# iospear320 register map
Registers are 32-bit, access not given, no defined reset value unless marked. A register's access mark holds for its fields unless they carry their own. Addresses are absolute; registers are grouped by the start of their names; [hi:lo] are bit positions; {n}, {i} and the like mark numbered series; 'fields as' and 'values as' point back to an identical list.

## SFR
0x40000060 timeout_reg
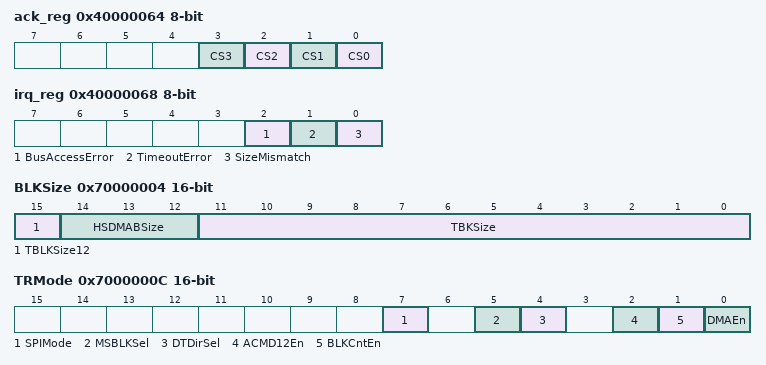
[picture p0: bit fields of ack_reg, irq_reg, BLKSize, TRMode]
0x40000064 ack_reg 8-bit
  [n] CS{n} (n=0..3)
0x40000068 irq_reg 8-bit
  [2] BusAccessError, [1] TimeoutError, [0] SizeMismatch
0x70000000 SDMASysAddr
0x70000004 BLKSize 16-bit
  [15] TBLKSize12, [14:12] HSDMABSize, [11:0] TBKSize
0x70000006 BLKCnt 16-bit
0x70000008 CMDARG
0x7000000C TRMode 16-bit
  [7] SPIMode, [5] MSBLKSel, [4] DTDirSel, [2] ACMD12En, [1] BLKCntEn, [0] DMAEn
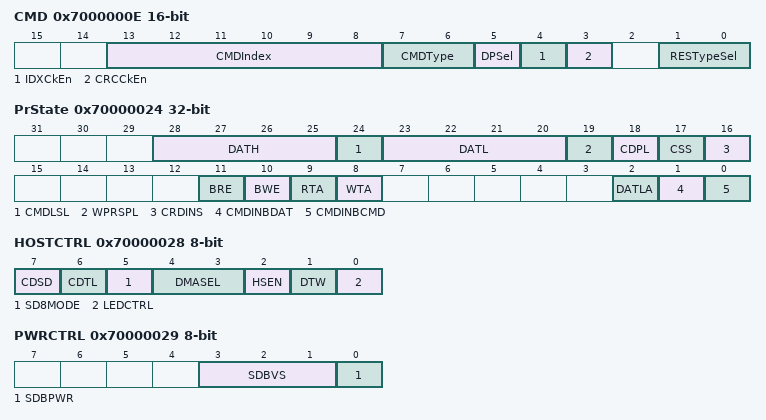
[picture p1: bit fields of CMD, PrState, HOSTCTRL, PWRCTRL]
0x7000000E CMD 16-bit
  [13:8] CMDIndex, [7:6] CMDType, [5] DPSel, [4] IDXCkEn, [3] CRCCkEn, [1:0] RESTypeSel
{0x70000010+4i} RESP{i} (i=0..3)
0x70000020 BufDataPort
0x70000024 PrState
  [28:25] DATH, [24] CMDLSL, [23:20] DATL, [19] WPRSPL, [18] CDPL, [17] CSS, [16] CRDINS, [11] BRE, [10] BWE, [9] RTA, [8] WTA, [2] DATLA, [1] CMDINBDAT, [0] CMDINBCMD
0x70000028 HOSTCTRL 8-bit
  [7] CDSD, [6] CDTL, [5] SD8MODE, [4:3] DMASEL, [2] HSEN, [1] DTW, [0] LEDCTRL
0x70000029 PWRCTRL 8-bit
  [3:1] SDBVS, [0] SDBPWR
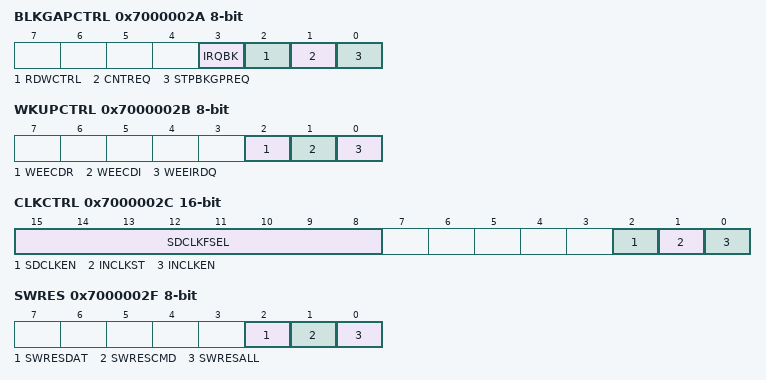
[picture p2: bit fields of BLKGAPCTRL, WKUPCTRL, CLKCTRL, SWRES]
0x7000002A BLKGAPCTRL 8-bit
  [3] IRQBK, [2] RDWCTRL, [1] CNTREQ, [0] STPBKGPREQ
0x7000002B WKUPCTRL 8-bit
  [2] WEECDR, [1] WEECDI, [0] WEEIRDQ
0x7000002C CLKCTRL 16-bit
  [15:8] SDCLKFSEL, [2] SDCLKEN, [1] INCLKST, [0] INCLKEN
0x7000002E TMOUTCTRL 8-bit
  [3:0] DATATMCNT
0x7000002F SWRES 8-bit
  [2] SWRESDAT, [1] SWRESCMD, [0] SWRESALL
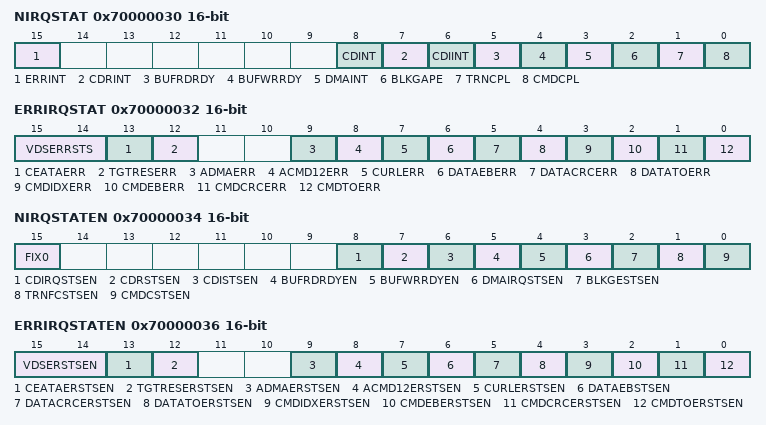
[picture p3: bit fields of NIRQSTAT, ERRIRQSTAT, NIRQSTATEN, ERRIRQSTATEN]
0x70000030 NIRQSTAT 16-bit
  [15] ERRINT, [8] CDINT, [7] CDRINT, [6] CDIINT, [5] BUFRDRDY, [4] BUFWRRDY, [3] DMAINT, [2] BLKGAPE, [1] TRNCPL, [0] CMDCPL
0x70000032 ERRIRQSTAT 16-bit
  [15:14] VDSERRSTS, [13] CEATAERR, [12] TGTRESERR, [9] ADMAERR, [8] ACMD12ERR, [7] CURLERR, [6] DATAEBERR, [5] DATACRCERR, [4] DATATOERR, [3] CMDIDXERR, [2] CMDEBERR, [1] CMDCRCERR, [0] CMDTOERR
0x70000034 NIRQSTATEN 16-bit
  [15] FIX0, [8] CDIRQSTSEN, [7] CDRSTSEN, [6] CDISTSEN, [5] BUFRDRDYEN, [4] BUFWRRDYEN, [3] DMAIRQSTSEN, [2] BLKGESTSEN, [1] TRNFCSTSEN, [0] CMDCSTSEN
0x70000036 ERRIRQSTATEN 16-bit
  [15:14] VDSERSTSEN, [13] CEATAERSTSEN, [12] TGTRESERSTSEN, [9] ADMAERSTSEN, [8] ACMD12ERSTSEN, [7] CURLERSTSEN, [6] DATAEBSTSEN, [5] DATACRCERSTSEN, [4] DATATOERSTSEN, [3] CMDIDXERSTSEN, [2] CMDEBERSTSEN, [1] CMDCRCERSTSEN, [0] CMDTOERSTSEN
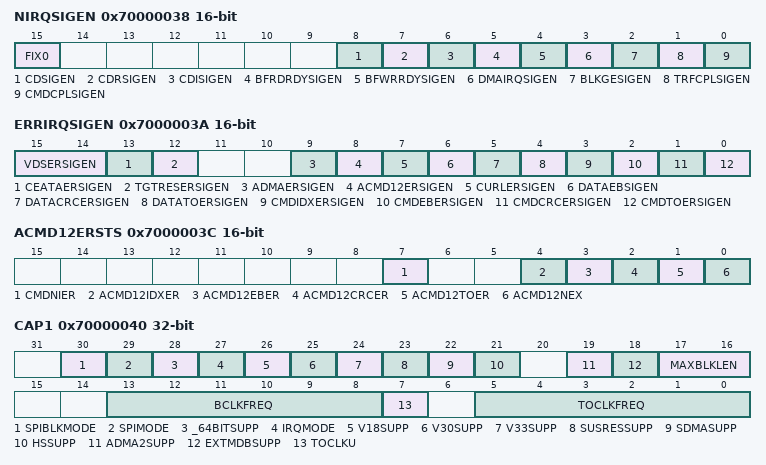
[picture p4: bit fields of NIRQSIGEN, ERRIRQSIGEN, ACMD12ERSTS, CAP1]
0x70000038 NIRQSIGEN 16-bit
  [15] FIX0, [8] CDSIGEN, [7] CDRSIGEN, [6] CDISIGEN, [5] BFRDRDYSIGEN, [4] BFWRRDYSIGEN, [3] DMAIRQSIGEN, [2] BLKGESIGEN, [1] TRFCPLSIGEN, [0] CMDCPLSIGEN
0x7000003A ERRIRQSIGEN 16-bit
  [15:14] VDSERSIGEN, [13] CEATAERSIGEN, [12] TGTRESERSIGEN, [9] ADMAERSIGEN, [8] ACMD12ERSIGEN, [7] CURLERSIGEN, [6] DATAEBSIGEN, [5] DATACRCERSIGEN, [4] DATATOERSIGEN, [3] CMDIDXERSIGEN, [2] CMDEBERSIGEN, [1] CMDCRCERSIGEN, [0] CMDTOERSIGEN
0x7000003C ACMD12ERSTS 16-bit
  [7] CMDNIER, [4] ACMD12IDXER, [3] ACMD12EBER, [2] ACMD12CRCER, [1] ACMD12TOER, [0] ACMD12NEX
0x70000040 CAP1
  [30] SPIBLKMODE, [29] SPIMODE, [28] _64BITSUPP, [27] IRQMODE, [26] V18SUPP, [25] V30SUPP, [24] V33SUPP, [23] SUSRESSUPP, [22] SDMASUPP, [21] HSSUPP, [19] ADMA2SUPP, [18] EXTMDBSUPP, [17:16] MAXBLKLEN, [13:8] BCLKFREQ, [7] TOCLKU, [5:0] TOCLKFREQ
0x70000044 CAP2
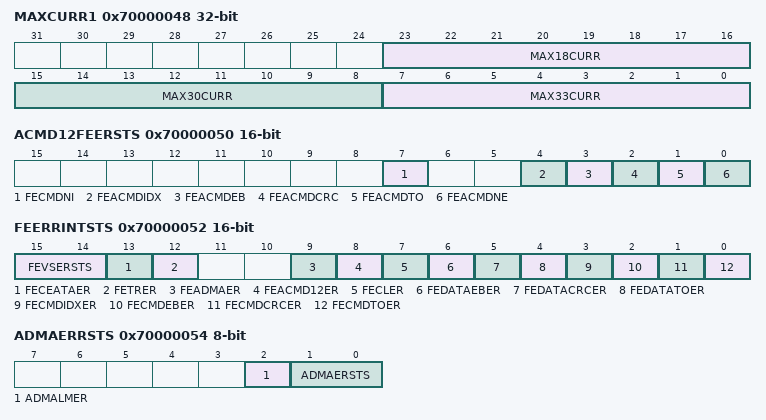
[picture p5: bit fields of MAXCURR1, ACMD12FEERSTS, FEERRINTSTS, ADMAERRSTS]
0x70000048 MAXCURR1
  [23:16] MAX18CURR, [15:8] MAX30CURR, [7:0] MAX33CURR
0x7000004C MAXCURR2
0x70000050 ACMD12FEERSTS 16-bit
  [7] FECMDNI, [4] FEACMDIDX, [3] FEACMDEB, [2] FEACMDCRC, [1] FEACMDTO, [0] FEACMDNE
0x70000052 FEERRINTSTS 16-bit
  [15:14] FEVSERSTS, [13] FECEATAER, [12] FETRER, [9] FEADMAER, [8] FEACMD12ER, [7] FECLER, [6] FEDATAEBER, [5] FEDATACRCER, [4] FEDATATOER, [3] FECMDIDXER, [2] FECMDEBER, [1] FECMDCRCER, [0] FECMDTOER
0x70000054 ADMAERRSTS 8-bit
  [2] ADMALMER, [1:0] ADMAERSTS
0x70000058 ADMAAddr1
0x7000005C ADMAAddr2
0x700000F0 SPIIRQSUPP 8-bit
0x700000FC SLTIRQSTS 8-bit
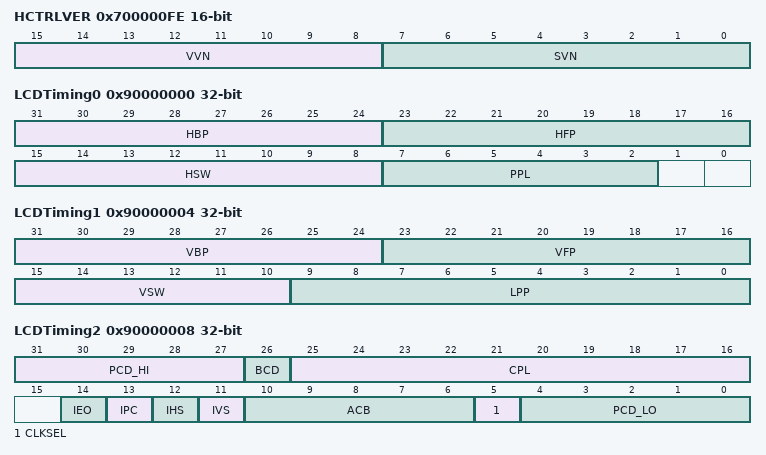
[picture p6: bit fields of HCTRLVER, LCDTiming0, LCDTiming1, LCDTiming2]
0x700000FE HCTRLVER 16-bit
  [15:8] VVN, [7:0] SVN
0x90000000 LCDTiming0
  [31:24] HBP, [23:16] HFP, [15:8] HSW, [7:2] PPL
0x90000004 LCDTiming1
  [31:24] VBP, [23:16] VFP, [15:10] VSW, [9:0] LPP
0x90000008 LCDTiming2
  [31:27] PCD_HI, [26] BCD, [25:16] CPL, [14] IEO, [13] IPC, [12] IHS, [11] IVS, [10:6] ACB, [5] CLKSEL, [4:0] PCD_LO
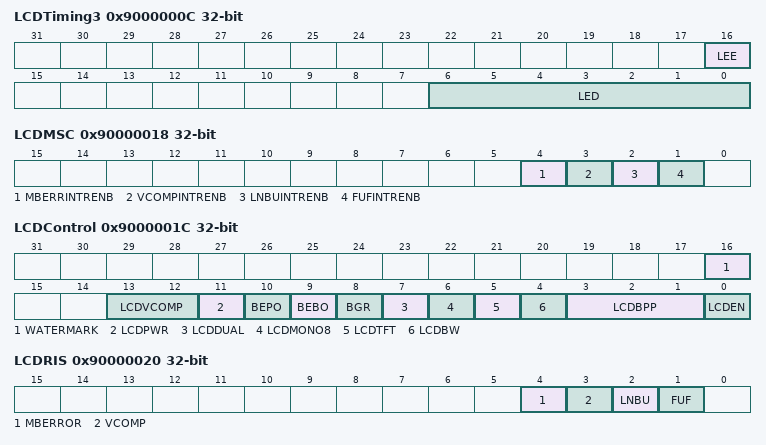
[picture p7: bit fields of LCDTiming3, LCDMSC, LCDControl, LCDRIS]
0x9000000C LCDTiming3
  [16] LEE, [6:0] LED
0x90000010 LCDUPBase
0x90000014 LCDLPBase
0x90000018 LCDMSC
  [4] MBERRINTRENB, [3] VCOMPINTRENB, [2] LNBUINTRENB, [1] FUFINTRENB
0x9000001C LCDControl
  [16] WATERMARK, [13:12] LCDVCOMP, [11] LCDPWR, [10] BEPO, [9] BEBO, [8] BGR, [7] LCDDUAL, [6] LCDMONO8, [5] LCDTFT, [4] LCDBW, [3:1] LCDBPP, [0] LCDEN
0x90000020 LCDRIS
  [4] MBERROR, [3] VCOMP, [2] LNBU, [1] FUF
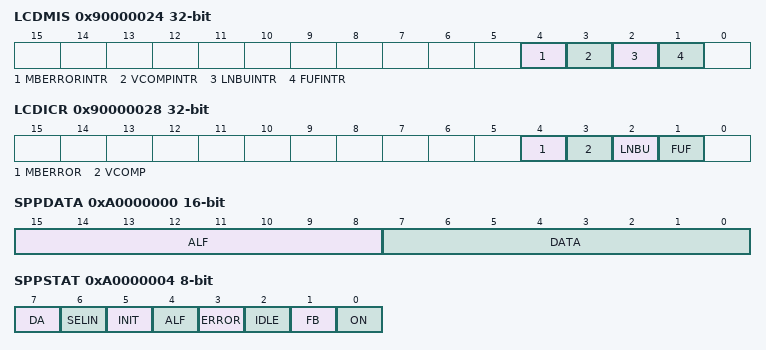
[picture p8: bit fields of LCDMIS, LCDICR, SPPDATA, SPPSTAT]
0x90000024 LCDMIS
  [4] MBERRORINTR, [3] VCOMPINTR, [2] LNBUINTR, [1] FUFINTR
0x90000028 LCDICR
  [4] MBERROR, [3] VCOMP, [2] LNBU, [1] FUF
0x9000002C LCDUPCUR
0x90000030 LCDLPCUR
0x90000200 LCDPaletteBase
{0x90000FE0+4i} LCDLPHERIPHID{i} (i=0..3)
{0x90000FF0+4i} LCDLPCELLIDID{i} (i=0..3)
0xA0000000 SPPDATA 16-bit
  [15:8] ALF, [7:0] DATA
0xA0000004 SPPSTAT 8-bit
  [7] DA, [6] SELIN, [5] INIT, [4] ALF, [3] ERROR, [2] IDLE, [1] FB, [0] ON
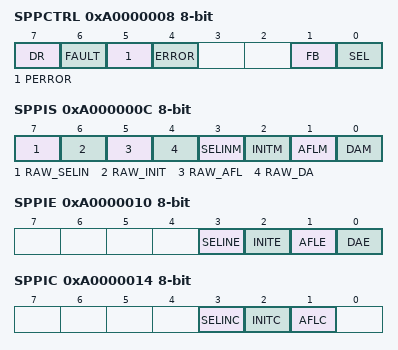
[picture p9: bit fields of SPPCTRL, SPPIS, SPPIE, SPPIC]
0xA0000008 SPPCTRL 8-bit
  [7] DR, [6] FAULT, [5] PERROR, [4] ERROR, [1] FB, [0] SEL
0xA000000C SPPIS 8-bit
  [7] RAW_SELIN, [6] RAW_INIT, [5] RAW_AFL, [4] RAW_DA, [3] SELINM, [2] INITM, [1] AFLM, [0] DAM
0xA0000010 SPPIE 8-bit
  [3] SELINE, [2] INITE, [1] AFLE, [0] DAE
0xA0000014 SPPIC 8-bit
  [3] SELINC, [2] INITC, [1] AFLC
0xA3000000 UART1DR 16-bit
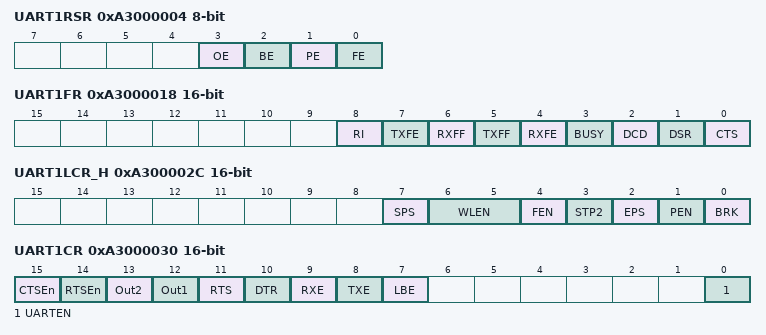
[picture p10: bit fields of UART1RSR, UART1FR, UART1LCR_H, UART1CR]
0xA3000004 UART1RSR 8-bit
  [3] OE, [2] BE, [1] PE, [0] FE
0xA3000004 UART1ECR 8-bit
0xA3000018 UART1FR 16-bit
  [8] RI, [7] TXFE, [6] RXFF, [5] TXFF, [4] RXFE, [3] BUSY, [2] DCD, [1] DSR, [0] CTS
0xA3000024 UART1IBRD 16-bit
0xA3000028 UART1FBRD 8-bit
  [5:0] DIVFRAC
0xA300002C UART1LCR_H 16-bit
  [7] SPS, [6:5] WLEN, [4] FEN, [3] STP2, [2] EPS, [1] PEN, [0] BRK
0xA3000030 UART1CR 16-bit
  [15] CTSEn, [14] RTSEn, [13] Out2, [12] Out1, [11] RTS, [10] DTR, [9] RXE, [8] TXE, [7] LBE, [0] UARTEN
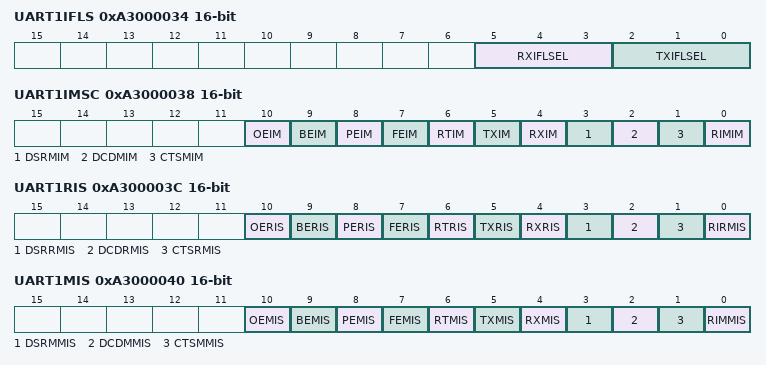
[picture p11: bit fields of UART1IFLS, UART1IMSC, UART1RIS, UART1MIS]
0xA3000034 UART1IFLS 16-bit
  [5:3] RXIFLSEL, [2:0] TXIFLSEL
0xA3000038 UART1IMSC 16-bit
  [10] OEIM, [9] BEIM, [8] PEIM, [7] FEIM, [6] RTIM, [5] TXIM, [4] RXIM, [3] DSRMIM, [2] DCDMIM, [1] CTSMIM, [0] RIMIM
0xA300003C UART1RIS 16-bit
  [10] OERIS, [9] BERIS, [8] PERIS, [7] FERIS, [6] RTRIS, [5] TXRIS, [4] RXRIS, [3] DSRRMIS, [2] DCDRMIS, [1] CTSRMIS, [0] RIRMIS
0xA3000040 UART1MIS 16-bit
  [10] OEMIS, [9] BEMIS, [8] PEMIS, [7] FEMIS, [6] RTMIS, [5] TXMIS, [4] RXMIS, [3] DSRMMIS, [2] DCDMMIS, [1] CTSMMIS, [0] RIMMIS
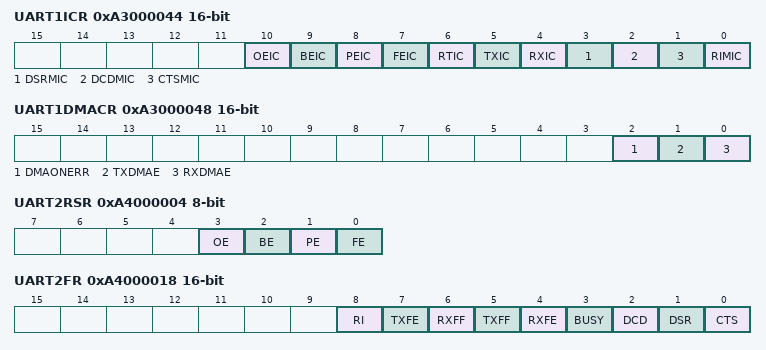
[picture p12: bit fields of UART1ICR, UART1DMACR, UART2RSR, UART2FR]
0xA3000044 UART1ICR 16-bit
  [10] OEIC, [9] BEIC, [8] PEIC, [7] FEIC, [6] RTIC, [5] TXIC, [4] RXIC, [3] DSRMIC, [2] DCDMIC, [1] CTSMIC, [0] RIMIC
0xA3000048 UART1DMACR 16-bit
  [2] DMAONERR, [1] TXDMAE, [0] RXDMAE
{0xA3000FE0+4i} UART1PeriphID{i} (i=0..3)
{0xA3000FF0+4i} UART1PCellID{i} (i=0..3)
0xA4000000 UART2DR 16-bit
0xA4000004 UART2RSR 8-bit
  [3] OE, [2] BE, [1] PE, [0] FE
0xA4000004 UART2ECR 8-bit
0xA4000018 UART2FR 16-bit
  fields as UART1FR
0xA4000024 UART2IBRD 16-bit
0xA4000028 UART2FBRD 8-bit
  [5:0] DIVFRAC
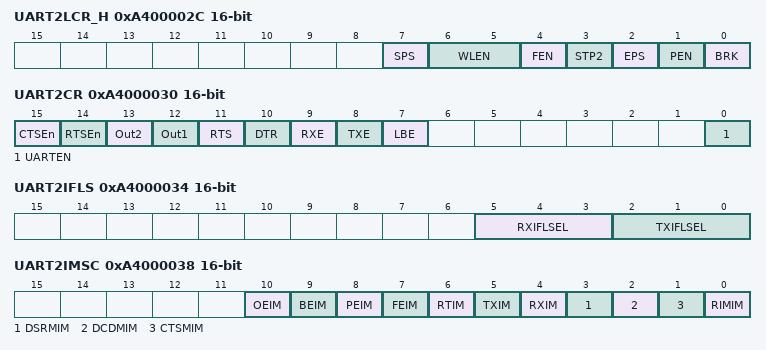
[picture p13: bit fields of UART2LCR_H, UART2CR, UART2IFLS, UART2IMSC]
0xA400002C UART2LCR_H 16-bit
  [7] SPS, [6:5] WLEN, [4] FEN, [3] STP2, [2] EPS, [1] PEN, [0] BRK
0xA4000030 UART2CR 16-bit
  fields as UART1CR
0xA4000034 UART2IFLS 16-bit
  [5:3] RXIFLSEL, [2:0] TXIFLSEL
0xA4000038 UART2IMSC 16-bit
  fields as UART1IMSC
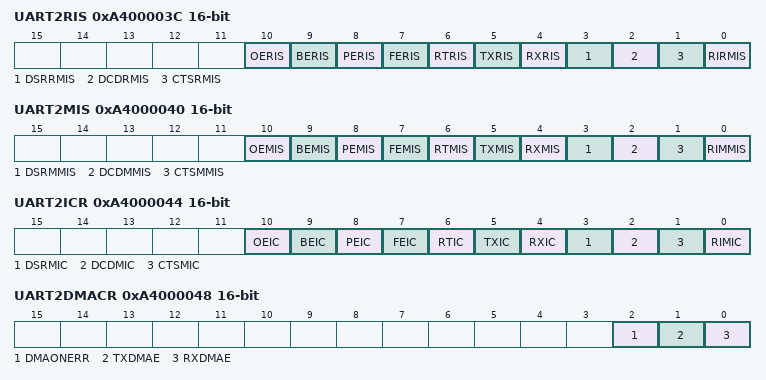
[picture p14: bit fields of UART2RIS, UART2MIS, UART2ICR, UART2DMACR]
0xA400003C UART2RIS 16-bit
  fields as UART1RIS
0xA4000040 UART2MIS 16-bit
  fields as UART1MIS
0xA4000044 UART2ICR 16-bit
  fields as UART1ICR
0xA4000048 UART2DMACR 16-bit
  [2] DMAONERR, [1] TXDMAE, [0] RXDMAE
{0xA4000FE0+4i} UART2PeriphID{i} (i=0..3)
{0xA4000FF0+4i} UART2PCellID{i} (i=0..3)
0xA5000000 SPI1CR0 16-bit
  [15:8] SCR, [7] SPH, [6] SPO, [5:4] FRF, [3:0] DSS
0xA5000004 SPI1CR1 16-bit
  [3] SOD, [2] MS, [1] SSE, [0] LBM
0xA5000008 SPI1DR 16-bit
0xA500000C SPI1SR 16-bit
  [4] BSY, [3] RFF, [2] RNE, [1] TNF, [0] TFE
0xA5000010 SPI1CPSR 16-bit
  [7:0] CPSDVSR
0xA5000014 SPI1IMSC 16-bit
  [3] TXIM, [2] RXIM, [1] RTIM, [0] RORIM
0xA5000018 SPI1RIS 16-bit
  [3] TXRIS, [2] RXRIS, [1] RTRIS, [0] RORRIS
0xA500001C SPI1MIS 16-bit
  [3] TXMIS, [2] RXMIS, [1] RTMIS, [0] RORMIS
0xA5000020 SPI1ICR 16-bit
  [1] RTIC, [0] RORIC
0xA5000024 SPI1DMACR 16-bit
  [1] TXDMAE, [0] RXDMAE
0xA5000FE0 SPI1PeriphID0 16-bit
  [7:0] PartNumber0
0xA5000FE4 SPI1PeriphID1 16-bit
  [7:4] Designer0, [3:0] PartNumber1
0xA5000FE8 SPI1PeriphID2 16-bit
  [7:4] Revision, [3:0] Designer1
0xA5000FEC SPI1PeriphID3 16-bit
  [7:0] Configuration
{0xA5000FF0+4i} SPI1CellID{i} 16-bit (i=0..3)
  [7:0] PCELLID{i}
0xA6000000 SPI2CR0 16-bit
  [15:8] SCR, [7] SPH, [6] SPO, [5:4] FRF, [3:0] DSS
0xA6000004 SPI2CR1 16-bit
  [3] SOD, [2] MS, [1] SSE, [0] LBM
0xA6000008 SPI2DR 16-bit
0xA600000C SPI2SR 16-bit
  [4] BSY, [3] RFF, [2] RNE, [1] TNF, [0] TFE
0xA6000010 SPI2CPSR 16-bit
  [7:0] CPSDVSR
0xA6000014 SPI2IMSC 16-bit
  [3] TXIM, [2] RXIM, [1] RTIM, [0] RORIM
0xA6000018 SPI2RIS 16-bit
  [3] TXRIS, [2] RXRIS, [1] RTRIS, [0] RORRIS
0xA600001C SPI2MIS 16-bit
  [3] TXMIS, [2] RXMIS, [1] RTMIS, [0] RORMIS
0xA6000020 SPI2ICR 16-bit
  [1] RTIC, [0] RORIC
0xA6000024 SPI2DMACR 16-bit
  [1] TXDMAE, [0] RXDMAE
0xA6000FE0 SPI2PeriphID0 16-bit
  [7:0] PartNumber0
0xA6000FE4 SPI2PeriphID1 16-bit
  [7:4] Designer0, [3:0] PartNumber1
0xA6000FE8 SPI2PeriphID2 16-bit
  [7:4] Revision, [3:0] Designer1
0xA6000FEC SPI2PeriphID3 16-bit
  [7:0] Configuration
{0xA6000FF0+4i} SPI2CellID{i} 16-bit (i=0..3)
  [7:0] PCELLID{i}
0xD0000000 UART0DR 16-bit
0xD0000004 UART0RSR 8-bit
  [3] OE, [2] BE, [1] PE, [0] FE
0xD0000004 UART0ECR 8-bit
0xD0000018 UART0FR 16-bit
  fields as UART1FR
0xD0000024 UART0IBRD 16-bit
0xD0000028 UART0FBRD 8-bit
  [5:0] DIVFRAC
0xD000002C UART0LCR_H 16-bit
  [7] SPS, [6:5] WLEN, [4] FEN, [3] STP2, [2] EPS, [1] PEN, [0] BRK
0xD0000030 UART0CR 16-bit
  fields as UART1CR
0xD0000034 UART0IFLS 16-bit
  [5:3] RXIFLSEL, [2:0] TXIFLSEL
0xD0000038 UART0IMSC 16-bit
  fields as UART1IMSC
0xD000003C UART0RIS 16-bit
  fields as UART1RIS
0xD0000040 UART0MIS 16-bit
  fields as UART1MIS
0xD0000044 UART0ICR 16-bit
  fields as UART1ICR
0xD0000048 UART0DMACR 16-bit
  [2] DMAONERR, [1] TXDMAE, [0] RXDMAE
{0xD0000FE0+4i} UART0PeriphID{i} (i=0..3)
{0xD0000FF0+4i} UART0PCellID{i} (i=0..3)
0xD0100000 SSPCR0 16-bit
  [15:8] SCR, [7] SPH, [6] SPO, [5:4] FRF, [3:0] DSS
0xD0100004 SSPCR1 16-bit
  [3] SOD, [2] MS, [1] SSE, [0] LBM
0xD0100008 SSPDR 16-bit
0xD010000C SSPSR 16-bit
  [4] BSY, [3] RFF, [2] RNE, [1] TNF, [0] TFE
0xD0100010 SSPCPSR 16-bit
  [7:0] CPSDVSR
0xD0100014 SSPIMSC 16-bit
  [3] TXIM, [2] RXIM, [1] RTIM, [0] RORIM
0xD0100018 SSPRIS 16-bit
  [3] TXRIS, [2] RXRIS, [1] RTRIS, [0] RORRIS
0xD010001C SSPMIS 16-bit
  [3] TXMIS, [2] RXMIS, [1] RTMIS, [0] RORMIS
0xD0100020 SSPICR 16-bit
  [1] RTIC, [0] RORIC
0xD0100024 SSPDMACR 16-bit
  [1] TXDMAE, [0] RXDMAE
0xD0100FE0 SSPPeriphID0 16-bit
  [7:0] PartNumber0
0xD0100FE4 SSPPeriphID1 16-bit
  [7:4] Designer0, [3:0] PartNumber1
0xD0100FE8 SSPPeriphID2 16-bit
  [7:4] Revision, [3:0] Designer1
0xD0100FEC SSPPeriphID3 16-bit
  [7:0] Configuration
{0xD0100FF0+4i} SSPCellID{i} 16-bit (i=0..3)
  [7:0] PCELLID{i}
0xD0800000 JPGCReg0
  [0] StartStop
0xD0800004 JPGCReg1
  [31:16] Ysiz, [8] Hdr, [7:6] Ns, [5:4] colspctype, [3] De, [2] Re, [1:0] Nf
0xD0800008 JPGCReg2
  [25:0] NMCU
0xD080000C JPGCReg3
  [31:16] Xsiz, [15:0] NRST
{0xD0800000+4i} JPGCReg{i} (i=4..7)
  [15:12] Vi, [11:8] Hi, [7:4] Nblocki, [3:2] QTi, [1] HAi, [0] HDi
0xD0800200 JPGCCS
  [31] EOC, [30] SCR, [17:3] LLI, [2:1] BNV, [0] INT
0xD0800204 JPGCBFIFO2C
0xD0800208 JPGCBC2FIFO
0xD080020C JPGCBCBI
  [31] EN, [30:0] BTF
0xD0800400 JPGCFifoIn
0xD0800600 JPGCFifoOut
0xD0800800 JPGCQMem
0xD0800C00 JPGCHuffMin
0xD0801000 JPGCHuffBase
0xD0801400 JPGCHuffSymb
0xD0801800 JPGCDHTMem
0xD0801C00 JPGCHuffEnc
0xE0800118 Txframecount_gb
0xE0800124 Tx64octects_gb
0xE0800128 Tx65to127octects_gb
0xE080012C Tx128to255octects_gb
0xE0800130 Tx256to511octects_gb
0xE0800134 Tx512to1023octects_gb
0xE0800138 Tx1024tomaxoctects_gb
0xE080013C Txunicastframes_gb
0xE0800148 Txunderflowerror
0xE080014C Txsinglecol_g
0xE0800150 Txmulticol_g
0xE0800154 Txdeferred
0xE0800158 Txlatecol
0xE080015C Txexesscol
0xE0800160 Txcarriererror
0xE0800168 Txexcessdef
0xE0800170 Txpauseframes
0xE0800174 Txvlanframes_g
0xE0800180 Rxframecount_gb
0xE080018C Rxbroadcastframes_g
0xE0800190 Rxmulticastframes_g
0xE0800194 Rxcrcerror
0xE0800198 Rxalignmenterror
0xE080019C Rxrunterror
0xE08001A0 Rxjabbererror
0xE08001A4 Rxundersize_g
0xE08001A8 Rxoversize_g
0xE08001AC Rx64octects_gb
0xE08001B0 Rx65to127octects_gb
0xE08001B4 Rx128to255octects_gb
0xE08001B8 Rx256to511octects_gb
0xE08001BC Rx512to1023octects_gb
0xE08001C0 Rx1023tomaxoctects_gb
0xE08001C4 Rxunicastframes_g
0xE08001C8 Rxlengtherror
0xE08001CC Rxoutofrangetype
0xE08001D0 Rxpauseframes
0xE08001D4 Rxfifooverflow
0xE08001D8 Rxvlanframes_gb
0xE08001DC Rxwatchdogerror
0xE1100000 UDEP0INCTRL
  [9] RRDY, [8] CNAK, [7] SNAK, [6] NAK, [5:4] ET, [3] P, [2] SN, [1] F, [0] S
0xE1100004 UDEP0INSTAT
  [23] ISOIN_DONE, [22:11] RX_PKT_SIZE, [10] TDC, [9] HE, [7] BNA, [6] IN, [5:4] OUT
0xE1100008 UDEP0INBS
  [17:16] ISO_PID, [15:0] BUFF_SIZE
0xE110000C UDEP0INMPS
  [31:16] BUFF_SIZE, [15:0] MAX_PKT_SIZE
0xE1100014 UDEP0INDDP
0xE1100018 UDEP0INWC
0xE1100020 UDEP1INCTRL
  fields as UDEP0INCTRL
0xE1100024 UDEP1INSTAT
  fields as UDEP0INSTAT
0xE1100028 UDEP1INBS
  [17:16] ISO_PID, [15:0] BUFF_SIZE
0xE110002C UDEP1INMPS
  [31:16] BUFF_SIZE, [15:0] MAX_PKT_SIZE
0xE1100034 UDEP1INDDP
0xE1100038 UDEP1INWC
0xE1100060 UDEP3INCTRL
  fields as UDEP0INCTRL
0xE1100064 UDEP3INSTAT
  fields as UDEP0INSTAT
0xE1100068 UDEP3INBS
  [17:16] ISO_PID, [15:0] BUFF_SIZE
0xE110006C UDEP3INMPS
  [31:16] BUFF_SIZE, [15:0] MAX_PKT_SIZE
0xE1100074 UDEP3INDDP
0xE1100078 UDEP3INWC
0xE11000A0 UDEP5INCTRL
  fields as UDEP0INCTRL
0xE11000A4 UDEP5INSTAT
  fields as UDEP0INSTAT
0xE11000A8 UDEP5INBS
  [17:16] ISO_PID, [15:0] BUFF_SIZE
0xE11000AC UDEP5INMPS
  [31:16] BUFF_SIZE, [15:0] MAX_PKT_SIZE
0xE11000B4 UDEP5INDDP
0xE11000B8 UDEP5INWC
0xE11000E0 UDEP7INCTRL
  fields as UDEP0INCTRL
0xE11000E4 UDEP7INSTAT
  fields as UDEP0INSTAT
0xE11000E8 UDEP7INBS
  [17:16] ISO_PID, [15:0] BUFF_SIZE
0xE11000EC UDEP7INMPS
  [31:16] BUFF_SIZE, [15:0] MAX_PKT_SIZE
0xE11000F4 UDEP7INDDP
0xE11000F8 UDEP7INWC
0xE1100120 UDEP9INCTRL
  fields as UDEP0INCTRL
0xE1100124 UDEP9INSTAT
  fields as UDEP0INSTAT
0xE1100128 UDEP9INBS
  [17:16] ISO_PID, [15:0] BUFF_SIZE
0xE110012C UDEP9INMPS
  [31:16] BUFF_SIZE, [15:0] MAX_PKT_SIZE
0xE1100134 UDEP9INDDP
0xE1100138 UDEP9INWC
0xE1100160 UDEP11INCTRL
  fields as UDEP0INCTRL
0xE1100164 UDEP11INSTAT
  fields as UDEP0INSTAT
0xE1100168 UDEP11INBS
  [17:16] ISO_PID, [15:0] BUFF_SIZE
0xE110016C UDEP11INMPS
  [31:16] BUFF_SIZE, [15:0] MAX_PKT_SIZE
0xE1100174 UDEP11INDDP
0xE1100178 UDEP11INWC
0xE11001A0 UDEP13INCTRL
  fields as UDEP0INCTRL
0xE11001A4 UDEP13INSTAT
  fields as UDEP0INSTAT
0xE11001A8 UDEP13INBS
  [17:16] ISO_PID, [15:0] BUFF_SIZE
0xE11001AC UDEP13INMPS
  [31:16] BUFF_SIZE, [15:0] MAX_PKT_SIZE
0xE11001B4 UDEP13INDDP
0xE11001B8 UDEP13INWC
0xE11001E0 UDEP15INCTRL
  fields as UDEP0INCTRL
0xE11001E4 UDEP15INSTAT
  fields as UDEP0INSTAT
0xE11001E8 UDEP15INBS
  [17:16] ISO_PID, [15:0] BUFF_SIZE
0xE11001EC UDEP15INMPS
  [31:16] BUFF_SIZE, [15:0] MAX_PKT_SIZE
0xE11001F4 UDEP15INDDP
0xE11001F8 UDEP15INWC
0xE1100200 UDEP0OUTCTRL
  fields as UDEP0INCTRL
0xE1100204 UDEP0OUTSTAT
  fields as UDEP0INSTAT
0xE1100208 UDEP0OUTPFN
  [17:16] ISO_PID, [15:0] BUFF_SIZE
0xE110020C UDEP0OUTBS
  [31:16] BUFF_SIZE, [15:0] MAX_PKT_SIZE
0xE1100210 UDEP0OUSBP
0xE1100214 UDEP0OUTDDP
0xE110021C UDEP0OUTRC
0xE1100240 UDEP2OUTCTRL
  fields as UDEP0INCTRL
0xE1100244 UDEP2OUTSTAT
  fields as UDEP0INSTAT
0xE1100248 UDEP2OUTPFN
  [17:16] ISO_PID, [15:0] BUFF_SIZE
0xE110024C UDEP2OUTBS
  [31:16] BUFF_SIZE, [15:0] MAX_PKT_SIZE
0xE1100250 UDEP2OUSBP
0xE1100254 UDEP2OUTDDP
0xE110025C UDEP2OUTRC
0xE1100280 UDEP4OUTCTRL
  fields as UDEP0INCTRL
0xE1100284 UDEP4OUTSTAT
  fields as UDEP0INSTAT
0xE1100288 UDEP4OUTPFN
  [17:16] ISO_PID, [15:0] BUFF_SIZE
0xE110028C UDEP4OUTBS
  [31:16] BUFF_SIZE, [15:0] MAX_PKT_SIZE
0xE1100290 UDEP4OUSBP
0xE1100294 UDEP4OUTDDP
0xE110029C UDEP4OUTRC
0xE11002C0 UDEP6OUTCTRL
  fields as UDEP0INCTRL
0xE11002C4 UDEP6OUTSTAT
  fields as UDEP0INSTAT
0xE11002C8 UDEP6OUTPFN
  [17:16] ISO_PID, [15:0] BUFF_SIZE
0xE11002CC UDEP6OUTBS
  [31:16] BUFF_SIZE, [15:0] MAX_PKT_SIZE
0xE11002D0 UDEP6OUSBP
0xE11002D4 UDEP6OUTDDP
0xE11002DC UDEP6OUTRC
0xE1100300 UDEP8OUTCTRL
  fields as UDEP0INCTRL
0xE1100304 UDEP8OUTSTAT
  fields as UDEP0INSTAT
0xE1100308 UDEP8OUTPFN
  [17:16] ISO_PID, [15:0] BUFF_SIZE
0xE110030C UDEP8OUTBS
  [31:16] BUFF_SIZE, [15:0] MAX_PKT_SIZE
0xE1100310 UDEP8OUSBP
0xE1100314 UDEP8OUTDDP
0xE110031C UDEP8OUTRC
0xE1100340 UDEP10OUTCTRL
  fields as UDEP0INCTRL
0xE1100344 UDEP10OUTSTAT
  fields as UDEP0INSTAT
0xE1100348 UDEP10OUTPFN
  [17:16] ISO_PID, [15:0] BUFF_SIZE
0xE110034C UDEP10OUTBS
  [31:16] BUFF_SIZE, [15:0] MAX_PKT_SIZE
0xE1100350 UDEP10OUSBP
0xE1100354 UDEP10OUTDDP
0xE110035C UDEP10OUTRC
0xE1100380 UDEP12OUTCTRL
  fields as UDEP0INCTRL
0xE1100384 UDEP12OUTSTAT
  fields as UDEP0INSTAT
0xE1100388 UDEP12OUTPFN
  [17:16] ISO_PID, [15:0] BUFF_SIZE
0xE110038C UDEP12OUTBS
  [31:16] BUFF_SIZE, [15:0] MAX_PKT_SIZE
0xE1100390 UDEP12OUSBP
0xE1100394 UDEP12OUTDDP
0xE110039C UDEP12OUTRC
0xE11003C0 UDEP14OUTCTRL
  fields as UDEP0INCTRL
0xE11003C4 UDEP14OUTSTAT
  fields as UDEP0INSTAT
0xE11003C8 UDEP14OUTPFN
  [17:16] ISO_PID, [15:0] BUFF_SIZE
0xE11003CC UDEP14OUTBS
  [31:16] BUFF_SIZE, [15:0] MAX_PKT_SIZE
0xE11003D0 UDEP14OUSBP
0xE11003D4 UDEP14OUTDDP
0xE11003DC UDEP14OUTRC
0xE1100400 UDDCFG
  [18] SET_DESC, [17] CSR_PRG, [16] HALT_STATUS, [15:13] HS_TIMEOUT_CALIB, [12:10] FS_TIMEOUT_CALIB, [9] PHY_ERROR_DETECT, [8] STATUS_1, [7] STATUS, [6] DIR, [5] PI, [4] SS, [3] SP, [2] RWKP, [1:0] SPD
0xE1100404 UDDCTRL
  [31:24] THLEN, [23:16] BRLEN, [13] CSR_DONE, [12] DEVNAK, [11] SCALE, [10] SD, [9] MODE, [8] BREN, [7] THE, [6] BF, [5] BE, [4] DU, [3] TDE, [2] RDE, [0] RES
0xE1100408 UDDSTAT
  [31:18] TS, [16] PHY_ERROR, [15] RXFIFO_EMPTY, [14:13] ENUM_SPD, [12] SUSP, [11:8] ALT, [7:4] INTF, [3:0] CFG
0xE110040C UDDINTR
  [6] ENUM, [5] SOF, [4] US, [3] UR, [2] ES, [1] SI, [0] SC
0xE1100410 UDDIM
  [6] ENUM, [5] SOF, [4] US, [3] UR, [2] ES, [1] SI, [0] SC
0xE1100414 UDEINTR
  [n+16] OUT_EP{n} (n=0..15), [n] IN_EP{n} (n=0..15)
0xE1100418 UDEIM
  [n+16] OUT_EP{n} (n=0..15), [n] IN_EP{n} (n=0..15)
{0xE1100504+4i} UDEP{i} (i=0..15)
  [29:19] MaxPackSize, [18:15] AltSetting, [14:11] InterfNumber, [10:7] ConfNumber, [6:5] EPType, [4] EPDir, [3:0] EPNumber
0xE1800000 HCCAPBASE
  [31:16] HCIVERSION, [7:0] CAPLENGTH
0xE1800004 HCSPARAMS
  [23:20] DPN, [16] P_INDICATOR, [15:12] N_CC, [11:8] N_PCC, [7] PRR, [4] PPC, [3:0] N_PORTS
0xE1800008 HCCPARAMS
  [15:8] EECP, [7:4] IST, [2] ASPC, [1] PFLF, [0] _64BAC
0xE1800010 HCUSBCMD
  [23:16] ITC, [11] ASPME, [9:8] ASPMC, [7] LHCR, [6] IAAD, [5] ASE, [4] PSE, [3:2] FLS, [1] HCRESET, [0] RS
0xE1800014 HCUSBSTS
  [15] ASS, [14] PSS, [13] R, [12] HH, [5] IAA, [4] HSE, [3] FLR, [2] PCD, [1] USBERRINT, [0] USBINT
0xE1800018 HCUSBINTR
  [5] IAAE, [4] HSEE, [3] FLRE, [2] PCIE, [1] EIE, [0] IE
0xE180001C HCFRINDEX
  [13:0] FRAME
0xE1800020 HCCTRLDSSEGMENT
0xE1800024 HCPERIODICLISTBASE
0xE1800028 HCASYNCLISTADDR
0xE1800050 HCCONFIGFLAG
  [0] CF
0xE1800054 HCPORTSC1
  [22] WKOC_E, [21] WKDSCNNT_E, [20] WKCNNT_E, [19:16] PTC, [15:14] PIC, [13] PO, [12] PP, [11:10] LS, [8] PR, [7] S, [6] FPR, [5] OcC, [4] OcA, [3] PEDC, [2] PEN, [1] CSC, [0] CCS
0xE1800058 HCPORTSC2
  fields as HCPORTSC1
0xE1800090 HCINSNREG00
  [13:0] RMFS
0xE1800094 HCINSNREG01
  [31:16] OUT, [15:0] IN
0xE1800098 HCINSNREG02
  [11:0] DEEP
0xE180009C HCINSNREG03
  [0] BMT
0xE18000A4 HCINSNREG05
  [17] VBusy, [16:13] VPort, [12] VControlLoadM, [11:8] VControl, [7:0] VStatus
0xE1900000 Hc1Revision
  [7:0] REV
0xE1900004 Hc1Control
  [10] RWE, [9] RWC, [8] IR, [7:6] HCFS, [5] BLE, [4] CLE, [3] IE, [2] PLE, [1:0] CBSR
0xE1900008 Hc1CommandStatus
  [17:16] SOC, [3] OCR, [2] BLF, [1] CLF, [0] HCR
0xE190000C Hc1InterruptStatus
  [30] OC, [6] RHSC, [5] FNO, [4] UE, [3] RD, [2] SF, [1] WDH, [0] SO
0xE1900010 Hc1InterruptEnable
  [31] MIE, [30] OC, [6] RHSC, [5] FNO, [4] UE, [3] RD, [2] SF, [1] WDH, [0] SO
0xE1900014 Hc1InterruptDisable
  fields as Hc1InterruptEnable
0xE1900018 Hc1HCCA
  [31:8] HCCA
0xE190001C Hc1PeriodCurrentED
  [31:4] PCED
0xE1900020 Hc1ControlHeadED
  [31:4] CHED
0xE1900024 Hc1ControlCurrentED
  [31:4] CCED
0xE1900028 Hc1BulkHeadED
  [31:4] BHED
0xE190002C Hc1BulkCurrentED
  [31:4] BCED
0xE1900030 Hc1DoneHead
  [31:4] DH
0xE1900034 Hc1FmInterval
  [31] FIT, [30:16] FSMPS, [13:0] FI
0xE1900038 Hc1FmRemaining
  [31] FRT, [13:0] FR
0xE190003C Hc1FmNumber
  [15:0] FN
0xE1900040 Hc1PeriodStart
  [13:0] PS
0xE1900044 Hc1LSThreshold
  [11:0] LST
0xE1900048 Hc1RhDescriptorA
  [31:24] POTPGT, [12] NOCP, [11] OCPM, [10] DT, [9] NPS, [8] PSM, [7:0] NDP
0xE190004C Hc1RhDescripterB
  [31:16] PPCM, [15:0] DR
0xE1900050 Hc1RhStatus
  [31] CRWE, [17] OCIC, [16] LPSC, [15] DRWE, [1] OCI, [0] LPS
0xE1900054 Hc1RhPortStatus
  [20] PRSC, [19] OCIC, [18] PSSC, [17] PESC, [16] CSC, [9] LSDA, [8] PPS, [4] PRS, [3] POCI, [2] PSS, [1] PES, [0] CCS
0xE2100000 Hc2Revision
  [7:0] REV
0xE2100004 Hc2Control
  fields as Hc1Control
0xE2100008 Hc2CommandStatus
  [17:16] SOC, [3] OCR, [2] BLF, [1] CLF, [0] HCR
0xE210000C Hc2InterruptStatus
  [30] OC, [6] RHSC, [5] FNO, [4] UE, [3] RD, [2] SF, [1] WDH, [0] SO
0xE2100010 Hc2InterruptEnable
  fields as Hc1InterruptEnable
0xE2100014 Hc2InterruptDisable
  fields as Hc1InterruptEnable
0xE2100018 Hc2HCCA
  [31:8] HCCA
0xE210001C Hc2PeriodCurrentED
  [31:4] PCED
0xE2100020 Hc2ControlHeadED
  [31:4] CHED
0xE2100024 Hc2ControlCurrentED
  [31:4] CCED
0xE2100028 Hc2BulkHeadED
  [31:4] BHED
0xE210002C Hc2BulkCurrentED
  [31:4] BCED
0xE2100030 Hc2DoneHead
  [31:4] DH
0xE2100034 Hc2FmInterval
  [31] FIT, [30:16] FSMPS, [13:0] FI
0xE2100038 Hc2FmRemaining
  [31] FRT, [13:0] FR
0xE210003C Hc2FmNumber
  [15:0] FN
0xE2100040 Hc2PeriodStart
  [13:0] PS
0xE2100044 Hc2LSThreshold
  [11:0] LST
0xE2100048 Hc2RhDescriptorA
  fields as Hc1RhDescriptorA
0xE210004C Hc2RhDescripterB
  [31:16] PPCM, [15:0] DR
0xE2100050 Hc2RhStatus
  [31] CRWE, [17] OCIC, [16] LPSC, [15] DRWE, [1] OCI, [0] LPS
0xE2100054 Hc2RhPortStatus
  fields as Hc1RhPortStatus
0xF1100000 VICIRQSTATUS
  [n] IRQStatus{n} (n=0..31)
0xF1100004 VICFIQSTATUS
  [n] FIQStatus{n} (n=0..31)
0xF1100008 VICRAWINTR
  [n] RawStatus{n} (n=0..31)
0xF110000C VICINTSELECT
  [n] IntSelect{n} (n=0..31)
0xF1100010 VICINTENABLE
  [n] IntEnable{n} (n=0..31)
0xF1100014 VICINTENCLEAR
  [n] IntEnableClear{n} (n=0..31)
0xF1100018 VICSOFTINT
  [n] SoftInt{n} (n=0..31)
0xF110001C VICSOFTINTCLEAR
  [n] SoftIntClear{n} (n=0..31)
0xF1100020 VICPROTECTION
  [0] Protection
0xF1100030 VICVECTADDR
0xF1100034 VICDEFVECTADDR
{0xF1100100+4i} VICVECTADDR{i} (i=0..15)
{0xF1100200+4i} VICVECTCNTL{i} (i=0..15)
  [5] E, [4:0] IntSource
0xF1100FE0 VICPERIPHID0 8-bit
0xF1100FE4 VICPERIPHID1 8-bit
  [7:4] Designer, [3:0] Partnumber
0xF1100FE8 VICPERIPHID2 8-bit
  [7:4] Revision, [3:0] Designer
0xF1100FEC VICPERIPHID3 8-bit
{0xF1100FF0+4i} VICPCELLID{i} 8-bit (i=0..3)
0xFC400000 DMACIntStatus
  [n] IntStatus{n} (n=0..7)
0xFC400004 DMACIntTCStatus
  [n] IntTCStatus{n} (n=0..7)
0xFC400008 DMACIntTCClear
  [n] IntTCClear{n} (n=0..7)
0xFC40000C DMACIntErrorStatus
  [n] IntErrorStatus{n} (n=0..7)
0xFC400010 DMACIntErrClr
  [n] IntErrClr{n} (n=0..7)
0xFC400014 DMACRawIntTCStatus
  [n] RawIntTCStatus{n} (n=0..7)
0xFC400018 DMACRawIntErrorStatus
  [n] RawIntErrorStatus{n} (n=0..7)
0xFC40001C DMACEnbldChns
  [n] EnabledChannels{n} (n=0..7)
0xFC400020 DMACSoftBReq
  [n] SoftBReq{n} (n=0..15)
0xFC400024 DMACSoftSReq
  [n] SoftSReq{n} (n=0..15)
0xFC400028 DMACSoftLBReq
  [n] SoftLBReq{n} (n=0..15)
0xFC40002C DMACSoftLSReq
  [n] SoftLSReq{n} (n=0..15)
0xFC400030 DMACConfiguration
  [2] M2, [1] M1, [0] E
0xFC400034 DMACSync
  [n] DMACSync{n} (n=0..15)
{0xFC400100+0x20*i} DMACC{i}SrcAddr (i=0..7)
{0xFC400104+0x20*i} DMACC{i}DestAddr (i=0..7)
{0xFC400108+0x20*i} DMACC{i}LLI (i=0..7)
  [31:2] LLI, [0] LM
{0xFC40010C+0x20*i} DMACC{i}Control (i=0..7)
  [31] I, [30:28] Port, [27] DI, [26] SI, [25] D, [24] S, [23:21] Dwidth, [20:18] Swidth, [17:15] DBSize, [14:12] SBSize, [11:0] TS
{0xFC400110+0x20*i} DMACC{i}Configuration (i=0..7)
  [18] H, [17] A, [16] L, [15] ITC, [14] IE, [13:11] FlowCntrl, [9:6] DestPeripheral, [4:1] SrcPeripheral, [0] E
0xFC600000 MEM0_CTL
  [27:24] AHB2_FIFO_TYPE, [19:16] AHB1_FIFO_TYPE, [11:8] AHB0_FIFO_TYPE, [3:0] ADDR_CMP_EN
0xFC600004 MEM1_CTL
  [9:8] AHB4_FIFO_TYPE, [1:0] AHB3_FIFO_TYPE
0xFC600008 MEM2_CTL
  [24] BANK_SPLI_EN, [16] AUTO_RFSH_MODE, [8] AREFRESH, [0] AP
0xFC60000C MEM3_CTL
  [24] DLL_BYPASS_MODE, [16] DLLLOCK, [8] DDRII_DDRI_MODE, [0] CONCURRENTAP
0xFC600010 MEM4_CTL
  [24] INTRPTAPBURST, [16] FAST_WRITE, [8] EIGHT_BANK_MODE, [0] DQS_N_EN
0xFC600014 MEM5_CTL
  [24] ODT_ADD_TURN_CLK_EN, [16] NOCMDINIT, [8] INTRPTWRITEA, [0] INTRPTREADA
0xFC600018 MEM6_CTL
  [24] REDUC, [16] PRIORITY_EN, [8] POWER_DOWN, [0] PLACEMENT_EN
0xFC60001C MEM7_CTL
  [24] START, [16] SREFRESH, [8] SW_SAME_EN, [0] REG_DIMM_EN
0xFC600020 MEM8_CTL
  [24] WRITE_MODE_REG, [16] WRITE_INTRPT, [8] WRRLC, [0] TRAS_LOCKOUT
0xFC600024 MEM9_CTL
  [25:24] ODT_RD_MAP_CS1, [17:16] ODT_RD_MAP_CS0, [9:8] MAX_CS, [1:0] CS_MAP
0xFC600028 MEM10_CTL
  [25:24] RTT_0, [17:16] OUTOFRANGETYPE, [9:8] ODT_WR_MAP_CS1, [1:0] ODT_WR_MAP_CS0
0xFC60002C MEM11_CTL
  [26:24] AHB0_R_PRIOTRITY, [18:16] AHB0_PORT_ORDERING, [10:8] ADDR_PINS, [1:0] RTT_PAD_TERMINATION
0xFC600030 MEM12_CTL
  [26:24] AHB1_W_PRIORITY, [18:16] AHB1_R_PRIORITY, [10:8] AHB1_PORT_ORDERING, [2:0] AHB0_W_PRIORITY
0xFC600034 MEM13_CTL
  [26:24] AHB3_PORT_ORDERING, [18:16] AHB2_W_PRIORITY, [10:8] AHB2_R_PRIORITY, [2:0] AHB2_PORT_ORDERING
0xFC600038 MEM14_CTL
  [26:24] AHB4_R_PRIORITY, [18:16] AHB4_PORT_ORDERING, [10:8] AHB3_W_PRIORITY, [2:0] AHB3_R_PRIORITY
0xFC60003C MEM15_CTL
  [2:0] AHB4_W_PRIORITY
0xFC600044 MEM17_CTL
  [26:24] TCKE, [18:16] OUT_OF_RANGE_SOURCE_ID, [10:8] COLUMN_SIZE, [2:0] CAS_LATENCY
0xFC600048 MEM18_CTL
  [26:24] TRTP, [18:16] TRRD, [2:0] TEMRS
0xFC60004C MEM19_CTL
  [26:24] WRLAT, [17:16] WRRWS, [10:8] TWTR, [2:0] TWR_INT
0xFC600050 MEM20_CTL
  [27:24] AHB0_P2RP, [19:16] AHB0_P1RP, [11:8] AHB0_P0RP, [5:0] AGE_COUNT
0xFC600054 MEM21_CTL
  [8n-21:8n-24] AHB0_P{n}RP (n=3..6)
0xFC600058 MEM22_CTL
  [27:24] AHB1_P2RP, [19:16] AHB1_P1RP, [11:8] AHB1_P0RP, [3:0] AHB0_P7RP
0xFC60005C MEM23_CTL
  [8n-21:8n-24] AHB1_P{n}RP (n=3..6)
0xFC600060 MEM24_CTL
  [27:24] AHB2_P2RP, [19:16] AHB2_P1RP, [11:8] AHB2_P0RP, [3:0] AHB1_P7RP
0xFC600064 MEM25_CTL
  [8n-21:8n-24] AHB2_P{n}RP (n=3..6)
0xFC600068 MEM26_CTL
  [27:24] AHB3_P2RP, [19:16] AHB3_P1RP, [11:8] AHB3_P0RP, [3:0] AHB2_P7RP
0xFC60006C MEM27_CTL
  [8n-21:8n-24] AHB3_P{n}RP (n=3..6)
0xFC600070 MEM28_CTL
  [27:24] AHB4_P2RP, [19:16] AHB4_P1RP, [11:8] AHB4_P0RP, [3:0] AHB3_P7RP
0xFC600074 MEM29_CTL
  [8n-21:8n-24] AHB4_P{n}RP (n=3..6)
0xFC600078 MEM30_CTL
  [3:0] AHB4_P7RP
0xFC600088 MEM34_CTL
  [27:24] CASLAT_LIN_GATE, [19:16] CASLAT_LIN, [11:8] APREBIT
0xFC60008C MEM35_CTL
  [27:24] MAX_ROW, [19:16] MAX_COL, [11:8] INITAREF, [5:0] COMMAND_AGE_COUNT
0xFC600090 MEM36_CTL
  [27:24] WRR_PARAM_VALUE_ERR, [19:16] TRP, [11:8] TDAL, [3:0] Q_FULLNESS
0xFC600094 MEM37_CTL
  [28:24] TFAW, [20:16] OCD_ADJUST_PUP_CS0, [12:8] OCD_ADJUST_PDN_CS0, [5:0] INT_ACK
0xFC600098 MEM38_CTL
  [30:24] INT_STATUS, [22:16] INT_MASK, [12:8] TRC, [4:0] TMRD
0xFC60009C MEM39_CTL
  [14:8] DLL_DQS_DELAY1, [6:0] DLL_DQS_DELA0
0xFC6000A0 MEM40_CTL
  [30:24] DQS_OUT_SHIFT
0xFC6000A4 MEM41_CTL
  [22:16] WR_DQS_SHIFT
0xFC6000A8 MEM42_CTL
  [31:24] TRFC, [23:16] TRCD_INT, [15:8] TRAS_MIN
0xFC6000AC MEM43_CTL
  [31:26] TRFC, [25:16] AHB1_PRIORITY_RELAX, [9:0] AHB0_PRIORITY_RELAX
0xFC6000B0 MEM44_CTL
  [31:26] TRFC, [25:16] AHB3_PRIORITY_RELAX, [9:0] AHB2_PRIORITY_RELAX
0xFC6000B4 MEM45_CTL
  [9:0] AHB4_PRIORITY_RELAX
0xFC6000B8 MEM46_CTL
  [25:16] OUT_OF_RANGE_LENGTH
{0xFC600000+4i} MEM{i}_CTL (i=47..51)
  [25:16] AHB{i-47}_WRCNT, [10:0] AHB{i-47}_RDCNT
0xFC6000D8 MEM54_CTL
  [13:0] TREF
0xFC6000DC MEM55_CTL
  [14:0] EMRS3_DATA
0xFC6000E0 MEM56_CTL
  [31:16] TRAS_MAX, [15:0] TDLL
0xFC6000E4 MEM57_CTL
  [31:16] TXSR, [15:0] TXSNR
0xFC6000E8 MEM58_CTL
  [15:0] VERSION
0xFC6000EC MEM59_CTL
  [23:0] TINIT
0xFC6000F0 MEM60_CTL
0xFC6000F4 MEM61_CTL
  [1:0] OUT_OF_RANGE_ADDR
0xFC600104 MEM65_CTL
  [25:16] DLL_DQS_DELAY_BYPASS_0
0xFC600108 MEM66_CTL
  [25:16] DLL_INCREMENT, [9:0] DLL_DQS_DELAY_BYPASS_1
0xFC60010C MEM67_CTL
  [25:16] DLL_START_POINT, [9:0] DLL_LOCK
0xFC600110 MEM68_CTL
  [25:16] WR_DQS_SHIFT_BYPASS, [9:0] DQS_OUT_SHIFT_BYPASS
0xFC600188 MEM98_CTL
0xFC60018C MEM99_CTL
0xFC600190 MEM100_CTL
  [24] ENABLE_QUICK_SREFRESH, [16] DRIVE_DQ_DQS, [8] BIG_ENDIAN_ENABLE, [0] ACTIVE_AGING
0xFC600194 MEM101_CTL
  [24] SWAP_ENABLE, [16] RD2RD_TURN, [8] PWRUP_SREFRESH_EXIT, [0] EN_LOWPOWER_MODE
0xFC600198 MEM102_CTL
  [28:24] LOWPOWER_AUTO_ENABLE, [18:16] CKE_DELAY, [9:8] LOWPOWER_REFRESH_ENABLE, [0] TREF_ENABLE
0xFC60019C MEM103_CTL
  [22:8] EMRS1_DATA, [4:0] LOWPOWER_CONTROL
0xFC6001A0 MEM104_CTL
  [30:16] EMRS2_DATA1, [14:0] EMRS2_DATA0
0xFC6001A4 MEM105_CTL
  [31:16] LOWPOWER_INT_CNT, [15:0] LOWPOWER_EXT_CNT
0xFC6001A8 MEM106_CTL
  [31:16] LOWPOWER_RFSH_HOLD, [15:0] LOWPOWER_PWDWN_CNT
0xFC6001AC MEM107_CTL
  [31:16] TCPD, [15:0] LOWPOWER_SRFSH_CNT
0xFC6001B0 MEM108_CTL
  [15:0] TPDEX
0xFC880000 WdogLoad
0xFC880004 WdogValue
0xFC880008 WdogControl
  [1] RESEN, [0] INTEN
0xFC88000C WdogIntClr
0xFC880010 WdogRIS
  [0] WDOGRIS
0xFC880018 WdogMIS
  [0] WDOGMIS
0xFC880C00 WdogLock
{0xFC880FE0+4i} WdogPeriphID{i} (i=0..3)
{0xFC880FF0+4i} WdogPCellID{i} (i=0..3)
0xFC900000 RTCTIME
  [21:20] HT, [19:16] HU, [14:12] MT, [11:8] MU, [6:4] ST, [3:0] SU
0xFC900004 RTCDATE
  [31:28] YM, [27:24] YH, [23:20] YT, [19:16] YU, [14:12] MT, [11:8] MU, [5:4] DT, [3:0] DU
0xFC900008 RTCALARMTIME
  [21:20] HT, [19:16] HU, [14:12] MT, [11:8] MU, [6:4] ST, [3:0] SU
0xFC90000C RTCALARMDATE
  fields as RTCDATE
0xFC900010 RTCCONTROL
  [31] IE, [9] TB, [8] PB, [5:0] MASK
0xFC900014 RTCSTATUS
  [31] I, [5] LD, [4] LT, [3] PD, [2] PT, [0] RC
0xFC900018 RTCREG1MC
0xFC90001C RTCREG2MC
0xFC9800FC GPIODATA 16-bit
  [n] GPIODATA{n} (n=0..7)
0xFC980400 GPIODIR 16-bit
  [n] GPIODIR{n} (n=0..5)
0xFC980404 GPIOIS 16-bit
  [n] GPIOIS{n} (n=0..5)
0xFC980408 GPIOIBE 16-bit
  [n] GPIOIBE{n} (n=0..5)
0xFC98040C GPIOIEV 16-bit
  [n] GPIOIEV{n} (n=0..5)
0xFC980410 GPIOIE 16-bit
  [n] GPIOIE{n} (n=0..5)
0xFC980414 GPIORIS 16-bit
  [n] GPIORIS{n} (n=0..5)
0xFC980418 GPIOMIS 16-bit
  [n] GPIOMIS{n} (n=0..5)
0xFC98041C GPIOIC 16-bit
  [n] GPIOIC{n} (n=0..5)
{0xFC980FE0+4i} GPIOPeriphID{i} 16-bit (i=0..3)
{0xFC980FF0+4i} GPIOPCellID{i} 16-bit (i=0..3)
0xFCA00000 SCCTRL
  [23] WDogEnOv, [20] TimerEn2Ov, [19] TimerEn2Sel, [18] TimerEn1Ov, [17] TimerEn1Sel, [16] TimerEn0Ov, [15] TimerEn0Sel, [14:12] HCLKDivSel, [9] RemapStat, [8] RemapClear, [6:3] ModeStatus, [2:0] ModeCtrl
0xFCA00004 SCSYSSTAT
0xFCA00008 SCIMCTRL
  [7] InMdType, [3:1] ItMdCtrl, [0] ItMdEn
0xFCA0000C SCIMSTAT
  [0] ItMdStat
0xFCA00010 SCXTALCTRL
  [18:3] XtalTime, [2] XtalStat, [1] XtalEn, [0] XtalOver
0xFCA00014 SCPLLCTRL
  [27:3] PllTime, [2] PllStat, [1] PllEn, [0] PllOver
{0xFCA00EE0+4i} SCSYSID{i} (i=0..3)
{0xFCA00FE0+4i} SCPeriphID{i} (i=0..3)
{0xFCA00FF0+4i} SCPCellID{i} (i=0..3)
0xFCA80000 SOC_CFG_CTR
  [19] boot_sel, [18:6] Fixed_Value, [5:0] SoC_cfg
0xFCA80004 DIAG_CFG_CTR
  [15] debug_freez, [11] sys_error, [5:4] SOC_dbg6
0xFCA80020 PLL_CLK_CFG
  [30:28] mctr_clk_sel, [26:24] pll2_clk_sel, [22:20] pll1_clk_sel, [19] mem_dll_lock, [18] usb_pll_lock, [17] sys_pll2_lock, [16] sys_pll1_lock, [2] pll3_enb_clkout, [1] pll2_enb_clkout, [0] pll1_enb_clkout
0xFCA80024 CORE_CLK_CFG
  [21:20] Osci24_div_ratio, [19] Osci24_div_en, [18] ras_synt34_clksel, [11:10] hclk_divsel, [9:8] pclk_ratio_lwsp, [5:4] pclk_ratio_basc, [1:0] pclk_ratio_arm1
0xFCA80028 PRPH_CLK_CFG
  [17] gptmr3_freez, [16] gptmr2_freez, [13] gptmr1_freez, [12] gptrmr3_clksel, [11] gptmr2_clksel, [8] gptmr1_clksel, [7] rtc_disable, [6:5] irda_clksel, [4] uart_clksel, [1] plltimeen, [0] xtaltimeen
{0xFCA80040+4i} PRSC{i}_CLK_CFG (i=1..3)
  [15:12] presc_n, [11:0] presc_m
0xFCA80050 AMEM_CFG_CTRL
  [31:24] amem_xdiv, [23:16] amem_ydiv, [15] amem_rst, [4] amem_synt_enb, [3:1] amem_clk_sel, [0] amem_clk_enb
0xFCA80060 IRDA_CLK_SYNT
  [31] synt_clk_enb, [30] synt_clkout_sel, [27:16] synt_xdiv, [11:0] synt_ydiv
0xFCA80064 UART_CLK_SYNT
  fields as IRDA_CLK_SYNT
{0xFCA80068+4i} RAS{i}_CLK_SYNT (i=1..4)
  fields as IRDA_CLK_SYNT
{0xFCA80078+4i} ICM{i}_ARB_CFG (i=1..9)
  [31] mtx_arb_type, [30:28] mxt_rndrb_pry_lyr, [3n+2:3n] mtx_fix_pry_lyr{n} (n=0..7)
0xFCA800E0 POWERDOWN_CFG_CTR
  [0] wakeup_fiq_enb
0xFCA800E4 COMPSSTL_1V8_CFG
  [31] TQ, [30:24] rasrc, [22:16] nasrc, [4] COMPOK, [3] accurate, [2] freeze, [1] comptq, [0] compen
0xFCA800EC COMPCOR_3V3_CFG
  fields as COMPSSTL_1V8_CFG
0xFCA800F0 DDR_PAD
  [18:15] DDR_SW_mode, [14] DDR_EN_PAD, [13] REFSSTL, [12] GATE_OPEN_mode, [10] ENZI, [9] DQS_PDN_sel, [8] DQS_PU_sel, [7] CLK_PDN_sel, [6] CLK_PU_sel, [5] PDN_sel, [4] PU_sel, [3] S_W_mode, [2] PROG_a, [1] PROG_b, [0] DDR_LOW_POWER_DDR2_mode
0xFCA80118 BIST5_STS_RES
  [31] bist_end, [n] bbad{n} (n=0..19)
0xFCA8011C SYSERR_CFG_CTR
  [28] DMA_err, [27] Mem_err, [26] usbh2_err, [25] usbh1_err, [24] usbdv_err, [23] arm2_wdg_err, [22] arm1_wdg_err, [15] mem_dll_err, [14] usb_pll_err, [13] sys_pll2_err, [12] sys_pll1_err, [10] DMA_err_enb, [9] mem_err_enb, [8] usb_err_enb, [6] wdg_err_enb, [4] pll_err_enb, [2] int_error, [1] int_error_rst, [0] int_error_enb
0xFCA80120 USB0_TUN_PRM
  [17:15] COMPDISTUNE, [14:12] SQRXTUNE, [11:8] TXFSLSTUNE, [7:4] TXVREFTUNE, [3] TXPREEMPHASISTUNE, [2:1] TXHSXVTUNE, [0] TXRISETUNE
0xFCA80124 USB_TUN_PRM
  fields as USB0_TUN_PRM
0xFCA80130 PLGPIO0_PAD_PRG
  [31] PDN_UART, [30] PUP_UART, [5n+4] PDN_{n} (n=0..5), [5n+3] PUP_{n} (n=0..5), [5n+2:5n+1] DRV_{n} (n=0..5), [5n] SLEW_{n} (n=0..5)
0xFCA80134 PLGPIO1_PAD_PRG
  [31] PDN_I2C, [30] PUP_I2C, [5n-26] PDN_{n} (n=6..11), [5n-27] PUP_{n} (n=6..11), [5n-28:5n-29] DRV_{n} (n=6..11), [5n-30] SLEW_{n} (n=6..11)
0xFCA80138 PLGPIO2_PAD_PRG
  [31] PDN_ETHERNET, [30] PUP_ETHERNET, [5n-56] PDN_{n} (n=12..17), [5n-57] PUP_{n} (n=12..17), [5n-58:5n-59] DRV_{n} (n=12..17), [5n-60] SLEW_{n} (n=12..17)
0xFCA8013C PLGPIO3_PAD_PRG
  [5n-86] PDN_{n} (n=18..23), [5n-87] PUP_{n} (n=18..23), [5n-88:5n-89] DRV_{n} (n=18..23), [5n-90] SLEW_{n} (n=18..23)
0xFCA80140 PLGPIO4_PAD_PRG
  [5n+4] PDN_CLK{n} (n=1..4), [5n+3] PUP_CLK{n} (n=1..4), [5n+2:5n+1] DRV_CLK{n} (n=1..4), [5n] SLEW_CLK{n} (n=1..4), [4] PDN_24, [3] PUP_24, [2:1] DRV_24
